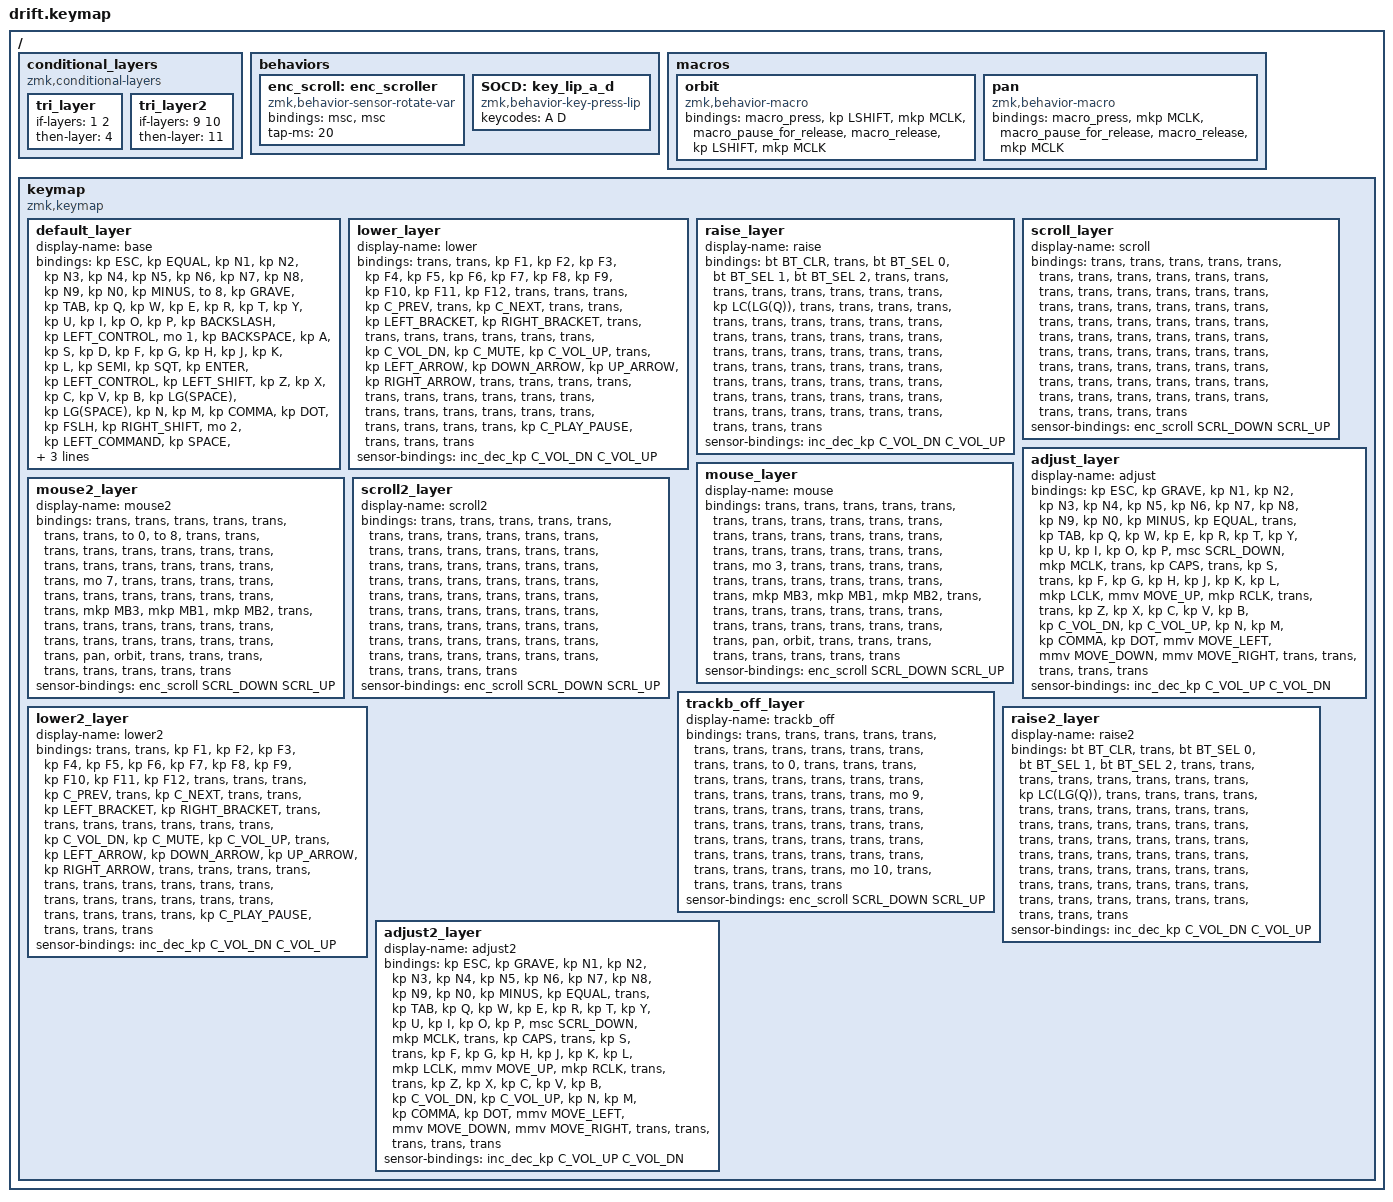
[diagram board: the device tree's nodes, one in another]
// Copyright (c) 2025 The ZMK Contributors
// SPDX-License-Identifier: MIT
// Default scroll sensitivity for encoder-based scrolling

#define ZMK_POINTING_DEFAULT_SCRL_VAL 100    // default was 10

#include <input/processors.dtsi>
#include <dt-bindings/zmk/mouse.h>
#include <behaviors/mouse_keys.dtsi>
#include <dt-bindings/zmk/input_transform.h>
#include <zephyr/dt-bindings/input/input-event-codes.h>
#include <behaviors.dtsi>
#include <dt-bindings/zmk/bt.h>
#include <dt-bindings/zmk/keys.h>
#include <dt-bindings/zmk/pointing.h>

// Keep all behavior settings visible in ZMK Studio

#define ZMK_BEHAVIORS_OMIT_KT

// Layer indices
// Order here must match the node order under / { keymap { } } below --
// that order IS the index. The shield overlay's input-processor blocks
// reference these numbers, so renumbering a layer means editing
// boards/shields/drift/drift_right_central.overlay too.

#define BASE        0
#define LOWER       1
#define RAISE       2
#define SCROLL      3
#define ADJUST      4
#define MOUSE       5
#define MOUSE2      6
#define SCROLL2     7
#define TRACKB_OFF  8
#define LOWER2      9
#define RAISE2      10
#define ADJUST2     11

// Reference: https://zmk.dev/docs/keymaps/behaviors/

/ {
    conditional_layers {
        compatible = "zmk,conditional-layers";

        tri_layer {
            if-layers = <1 2>;
            then-layer = <4>;
        };

        tri_layer2 {
            if-layers = <9 10>;
            then-layer = <11>;
        };
    };

    behaviors {
        enc_scroll: enc_scroller {
            compatible = "zmk,behavior-sensor-rotate-var";
            #sensor-binding-cells = <2>;
            bindings = <&msc>, <&msc>;

            tap-ms = <20>;
        };

        /* Setup left and right */

        SOCD: key_lip_a_d {
            compatible = "zmk,behavior-key-press-lip";
            #binding-cells = <1>;
            keycodes = <A D>;
        };
    };

    macros {
        orbit: orbit {
            compatible = "zmk,behavior-macro";
            #binding-cells = <0>;
            bindings =
                <&macro_press>,
                <&kp LSHIFT &mkp MCLK>,
                <&macro_pause_for_release>,
                <&macro_release>,
                <&kp LSHIFT &mkp MCLK>;
        };

        pan: pan {
            compatible = "zmk,behavior-macro";
            #binding-cells = <0>;
            bindings =
                <&macro_press>,
                <&mkp MCLK>,
                <&macro_pause_for_release>,
                <&macro_release>,
                <&mkp MCLK>;
        };
    };

    keymap {
        compatible = "zmk,keymap";

        // -------------------------------------------------------------------------------
        // BASE Layer
        // -------------------------------------------------------------------------------

        default_layer {
            display-name = "base";
            bindings = <
&kp ESC           &kp EQUAL       &kp N1  &kp N2            &kp N3     &kp N4                    &kp N5                                           &kp N6             &kp N7  &kp N8     &kp N9   &kp N0    &kp MINUS        &to 8
&kp GRAVE         &kp TAB         &kp Q   &kp W             &kp E      &kp R                     &kp T                                            &kp Y              &kp U   &kp I      &kp O    &kp P     &kp BACKSLASH    &kp LEFT_CONTROL
&mo 1             &kp BACKSPACE   &kp A   &kp S             &kp D      &kp F                     &kp G                                            &kp H              &kp J   &kp K      &kp L    &kp SEMI  &kp SQT          &kp ENTER
&kp LEFT_CONTROL  &kp LEFT_SHIFT  &kp Z   &kp X             &kp C      &kp V                     &kp B   &kp LG(SPACE)  &kp LG(SPACE)             &kp N              &kp M   &kp COMMA  &kp DOT  &kp FSLH  &kp RIGHT_SHIFT  &mo 2
                                          &kp LEFT_COMMAND  &kp SPACE  &mt (LEFT_ALT) LC(SPACE)                         &mt (LEFT_ALT) LC(SPACE)  &kp RIGHT_COMMAND
            >;

            sensor-bindings = <&enc_scroll SCRL_DOWN SCRL_UP>;
        };

        lower_layer {
            display-name = "lower";
            bindings = <
&trans  &trans  &kp F1  &kp F2        &kp F3            &kp F4        &kp F5                  &kp F6          &kp F7            &kp F8             &kp F9           &kp F10  &kp F11  &kp F12
&trans  &trans  &trans  &kp C_PREV    &trans            &kp C_NEXT    &trans                  &trans          &kp LEFT_BRACKET  &kp RIGHT_BRACKET  &trans           &trans   &trans   &trans
&trans  &trans  &trans  &kp C_VOL_DN  &kp C_MUTE        &kp C_VOL_UP  &trans                  &kp LEFT_ARROW  &kp DOWN_ARROW    &kp UP_ARROW       &kp RIGHT_ARROW  &trans   &trans   &trans
&trans  &trans  &trans  &trans        &trans            &trans        &trans  &trans  &trans  &trans          &trans            &trans             &trans           &trans   &trans   &trans
                        &trans        &kp C_PLAY_PAUSE  &trans                        &trans  &trans
            >;

            sensor-bindings = <&inc_dec_kp C_VOL_DN C_VOL_UP>;
        };

        raise_layer {
            display-name = "raise";
            bindings = <
&bt BT_CLR  &trans  &bt BT_SEL 0  &bt BT_SEL 1  &bt BT_SEL 2  &trans  &trans                  &trans  &trans  &trans  &trans  &trans  &trans  &kp LC(LG(Q))
&trans      &trans  &trans        &trans        &trans        &trans  &trans                  &trans  &trans  &trans  &trans  &trans  &trans  &trans
&trans      &trans  &trans        &trans        &trans        &trans  &trans                  &trans  &trans  &trans  &trans  &trans  &trans  &trans
&trans      &trans  &trans        &trans        &trans        &trans  &trans  &trans  &trans  &trans  &trans  &trans  &trans  &trans  &trans  &trans
                                  &trans        &trans        &trans                  &trans  &trans
            >;

            sensor-bindings = <&inc_dec_kp C_VOL_DN C_VOL_UP>;
        };

        scroll_layer {
            display-name = "scroll";
            bindings = <
&trans  &trans  &trans  &trans  &trans  &trans  &trans                  &trans  &trans  &trans  &trans  &trans  &trans  &trans
&trans  &trans  &trans  &trans  &trans  &trans  &trans                  &trans  &trans  &trans  &trans  &trans  &trans  &trans
&trans  &trans  &trans  &trans  &trans  &trans  &trans                  &trans  &trans  &trans  &trans  &trans  &trans  &trans
&trans  &trans  &trans  &trans  &trans  &trans  &trans  &trans  &trans  &trans  &trans  &trans  &trans  &trans  &trans  &trans
                        &trans  &trans  &trans                  &trans  &trans
            >;

            sensor-bindings = <&enc_scroll SCRL_DOWN SCRL_UP>;
        };

        adjust_layer {
            display-name = "adjust";
            bindings = <
&kp ESC  &kp GRAVE  &kp N1  &kp N2  &kp N3  &kp N4  &kp N5                              &kp N6  &kp N7  &kp N8     &kp N9   &kp N0          &kp MINUS       &kp EQUAL
&trans   &kp TAB    &kp Q   &kp W   &kp E   &kp R   &kp T                               &kp Y   &kp U   &kp I      &kp O    &kp P           &msc SCRL_DOWN  &mkp MCLK
&trans   &kp CAPS   &trans  &kp S   &trans  &kp F   &kp G                               &kp H   &kp J   &kp K      &kp L    &mkp LCLK       &mmv MOVE_UP    &mkp RCLK
&trans   &trans     &kp Z   &kp X   &kp C   &kp V   &kp B   &kp C_VOL_DN  &kp C_VOL_UP  &kp N   &kp M   &kp COMMA  &kp DOT  &mmv MOVE_LEFT  &mmv MOVE_DOWN  &mmv MOVE_RIGHT
                            &trans  &trans  &trans                        &trans        &trans
            >;

            sensor-bindings = <&inc_dec_kp C_VOL_UP C_VOL_DN>;
        };

        mouse_layer {
            display-name = "mouse";
            bindings = <
&trans  &trans  &trans  &trans  &trans  &trans  &trans                  &trans  &trans    &trans    &trans    &trans  &trans  &trans
&trans  &trans  &trans  &trans  &trans  &trans  &trans                  &trans  &trans    &trans    &mo 3     &trans  &trans  &trans
&trans  &trans  &trans  &trans  &trans  &trans  &trans                  &trans  &mkp MB3  &mkp MB1  &mkp MB2  &trans  &trans  &trans
&trans  &trans  &trans  &trans  &trans  &trans  &trans  &trans  &trans  &trans  &trans    &pan      &orbit    &trans  &trans  &trans
                        &trans  &trans  &trans                  &trans  &trans
            >;

            sensor-bindings = <&enc_scroll SCRL_DOWN SCRL_UP>;
        };

        mouse2_layer {
            display-name = "mouse2";
            bindings = <
&trans  &trans  &trans  &trans  &trans  &trans  &trans                  &to 0   &to 8     &trans    &trans    &trans  &trans  &trans
&trans  &trans  &trans  &trans  &trans  &trans  &trans                  &trans  &trans    &trans    &mo 7     &trans  &trans  &trans
&trans  &trans  &trans  &trans  &trans  &trans  &trans                  &trans  &mkp MB3  &mkp MB1  &mkp MB2  &trans  &trans  &trans
&trans  &trans  &trans  &trans  &trans  &trans  &trans  &trans  &trans  &trans  &trans    &pan      &orbit    &trans  &trans  &trans
                        &trans  &trans  &trans                  &trans  &trans
            >;

            sensor-bindings = <&enc_scroll SCRL_DOWN SCRL_UP>;
        };

        scroll2_layer {
            display-name = "scroll2";
            bindings = <
&trans  &trans  &trans  &trans  &trans  &trans  &trans                  &trans  &trans  &trans  &trans  &trans  &trans  &trans
&trans  &trans  &trans  &trans  &trans  &trans  &trans                  &trans  &trans  &trans  &trans  &trans  &trans  &trans
&trans  &trans  &trans  &trans  &trans  &trans  &trans                  &trans  &trans  &trans  &trans  &trans  &trans  &trans
&trans  &trans  &trans  &trans  &trans  &trans  &trans  &trans  &trans  &trans  &trans  &trans  &trans  &trans  &trans  &trans
                        &trans  &trans  &trans                  &trans  &trans
            >;

            sensor-bindings = <&enc_scroll SCRL_DOWN SCRL_UP>;
        };

        trackb_off_layer {
            display-name = "trackb_off";
            bindings = <
&trans  &trans  &trans  &trans  &trans  &trans  &trans                  &trans  &trans  &trans  &trans  &trans  &trans  &to 0
&trans  &trans  &trans  &trans  &trans  &trans  &trans                  &trans  &trans  &trans  &trans  &trans  &trans  &trans
&mo 9   &trans  &trans  &trans  &trans  &trans  &trans                  &trans  &trans  &trans  &trans  &trans  &trans  &trans
&trans  &trans  &trans  &trans  &trans  &trans  &trans  &trans  &trans  &trans  &trans  &trans  &trans  &trans  &trans  &mo 10
                        &trans  &trans  &trans                  &trans  &trans
            >;

            sensor-bindings = <&enc_scroll SCRL_DOWN SCRL_UP>;
        };

        lower2_layer {
            display-name = "lower2";
            bindings = <
&trans  &trans  &kp F1  &kp F2        &kp F3            &kp F4        &kp F5                  &kp F6          &kp F7            &kp F8             &kp F9           &kp F10  &kp F11  &kp F12
&trans  &trans  &trans  &kp C_PREV    &trans            &kp C_NEXT    &trans                  &trans          &kp LEFT_BRACKET  &kp RIGHT_BRACKET  &trans           &trans   &trans   &trans
&trans  &trans  &trans  &kp C_VOL_DN  &kp C_MUTE        &kp C_VOL_UP  &trans                  &kp LEFT_ARROW  &kp DOWN_ARROW    &kp UP_ARROW       &kp RIGHT_ARROW  &trans   &trans   &trans
&trans  &trans  &trans  &trans        &trans            &trans        &trans  &trans  &trans  &trans          &trans            &trans             &trans           &trans   &trans   &trans
                        &trans        &kp C_PLAY_PAUSE  &trans                        &trans  &trans
            >;

            sensor-bindings = <&inc_dec_kp C_VOL_DN C_VOL_UP>;
        };

        raise2_layer {
            display-name = "raise2";
            bindings = <
&bt BT_CLR  &trans  &bt BT_SEL 0  &bt BT_SEL 1  &bt BT_SEL 2  &trans  &trans                  &trans  &trans  &trans  &trans  &trans  &trans  &kp LC(LG(Q))
&trans      &trans  &trans        &trans        &trans        &trans  &trans                  &trans  &trans  &trans  &trans  &trans  &trans  &trans
&trans      &trans  &trans        &trans        &trans        &trans  &trans                  &trans  &trans  &trans  &trans  &trans  &trans  &trans
&trans      &trans  &trans        &trans        &trans        &trans  &trans  &trans  &trans  &trans  &trans  &trans  &trans  &trans  &trans  &trans
                                  &trans        &trans        &trans                  &trans  &trans
            >;

            sensor-bindings = <&inc_dec_kp C_VOL_DN C_VOL_UP>;
        };

        adjust2_layer {
            display-name = "adjust2";
            bindings = <
&kp ESC  &kp GRAVE  &kp N1  &kp N2  &kp N3  &kp N4  &kp N5                              &kp N6  &kp N7  &kp N8     &kp N9   &kp N0          &kp MINUS       &kp EQUAL
&trans   &kp TAB    &kp Q   &kp W   &kp E   &kp R   &kp T                               &kp Y   &kp U   &kp I      &kp O    &kp P           &msc SCRL_DOWN  &mkp MCLK
&trans   &kp CAPS   &trans  &kp S   &trans  &kp F   &kp G                               &kp H   &kp J   &kp K      &kp L    &mkp LCLK       &mmv MOVE_UP    &mkp RCLK
&trans   &trans     &kp Z   &kp X   &kp C   &kp V   &kp B   &kp C_VOL_DN  &kp C_VOL_UP  &kp N   &kp M   &kp COMMA  &kp DOT  &mmv MOVE_LEFT  &mmv MOVE_DOWN  &mmv MOVE_RIGHT
                            &trans  &trans  &trans                        &trans        &trans
            >;

            sensor-bindings = <&inc_dec_kp C_VOL_UP C_VOL_DN>;
        };
    };
};
